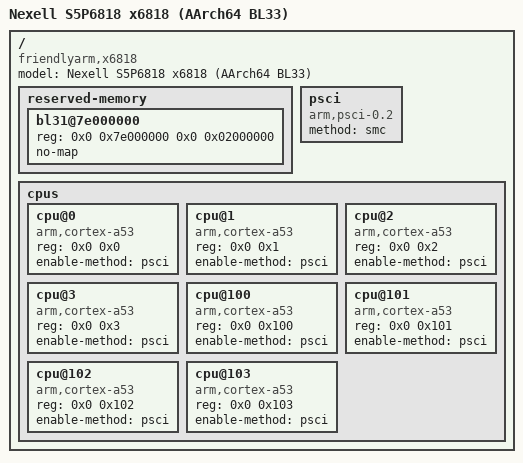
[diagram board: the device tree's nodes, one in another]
// SPDX-License-Identifier: GPL-2.0+
/*
 * Nexell S5P6818 x6818 AArch64 BL33 device tree.
 *
 * Reuse the board peripheral description, but never import the persistent
 * AArch32 environment during migration.
 */

#include "s5p6818-x6818.dts"

/ {
	model = "Nexell S5P6818 x6818 (AArch64 BL33)";
	compatible = "friendlyarm,x6818", "nexell,s5p6818";

	/delete-node/ config;

	reserved-memory {
		#address-cells = <2>;
		#size-cells = <2>;
		ranges;

		bl31@7e000000 {
			reg = <0x0 0x7e000000 0x0 0x02000000>;
			no-map;
		};
	};

	psci {
		compatible = "arm,psci-0.2";
		method = "smc";
	};

	cpus {
		#address-cells = <2>;
		#size-cells = <0>;

		cpu@0 {
			device_type = "cpu";
			compatible = "arm,cortex-a53";
			reg = <0x0 0x0>;
			enable-method = "psci";
		};

		cpu@1 {
			device_type = "cpu";
			compatible = "arm,cortex-a53";
			reg = <0x0 0x1>;
			enable-method = "psci";
		};

		cpu@2 {
			device_type = "cpu";
			compatible = "arm,cortex-a53";
			reg = <0x0 0x2>;
			enable-method = "psci";
		};

		cpu@3 {
			device_type = "cpu";
			compatible = "arm,cortex-a53";
			reg = <0x0 0x3>;
			enable-method = "psci";
		};

		cpu@100 {
			device_type = "cpu";
			compatible = "arm,cortex-a53";
			reg = <0x0 0x100>;
			enable-method = "psci";
		};

		cpu@101 {
			device_type = "cpu";
			compatible = "arm,cortex-a53";
			reg = <0x0 0x101>;
			enable-method = "psci";
		};

		cpu@102 {
			device_type = "cpu";
			compatible = "arm,cortex-a53";
			reg = <0x0 0x102>;
			enable-method = "psci";
		};

		cpu@103 {
			device_type = "cpu";
			compatible = "arm,cortex-a53";
			reg = <0x0 0x103>;
			enable-method = "psci";
		};
	};
};
